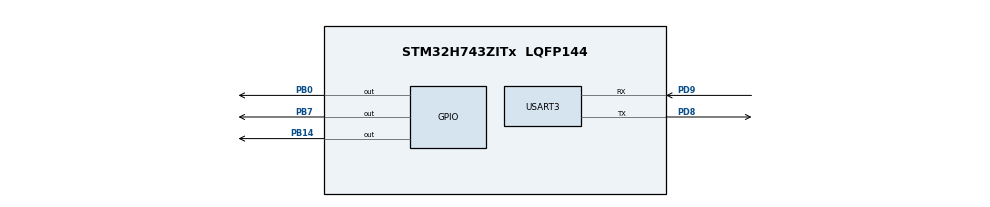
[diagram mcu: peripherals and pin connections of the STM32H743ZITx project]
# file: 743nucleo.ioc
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CORTEX_M7.AccessPermission-Cortex_Memory_Protection_Unit_Region0_Settings=MPU_REGION_PRIV_RO_URO
CORTEX_M7.AccessPermission-Cortex_Memory_Protection_Unit_Region1_Settings=MPU_REGION_FULL_ACCESS
CORTEX_M7.AccessPermission-Cortex_Memory_Protection_Unit_Region2_Settings=MPU_REGION_FULL_ACCESS
CORTEX_M7.AccessPermission-Cortex_Memory_Protection_Unit_Region3_Settings=MPU_REGION_FULL_ACCESS
CORTEX_M7.AccessPermission-Cortex_Memory_Protection_Unit_Region4_Settings=MPU_REGION_FULL_ACCESS
CORTEX_M7.AccessPermission-Cortex_Memory_Protection_Unit_Region5_Settings=MPU_REGION_FULL_ACCESS
CORTEX_M7.AccessPermission-Cortex_Memory_Protection_Unit_Region6_Settings=MPU_REGION_FULL_ACCESS
CORTEX_M7.BaseAddress-Cortex_Memory_Protection_Unit_Region0_Settings=0x08000000
CORTEX_M7.BaseAddress-Cortex_Memory_Protection_Unit_Region1_Settings=0x24000000
CORTEX_M7.BaseAddress-Cortex_Memory_Protection_Unit_Region2_Settings=0x30000000
CORTEX_M7.BaseAddress-Cortex_Memory_Protection_Unit_Region3_Settings=0x30020000
CORTEX_M7.BaseAddress-Cortex_Memory_Protection_Unit_Region4_Settings=0x30040000
CORTEX_M7.BaseAddress-Cortex_Memory_Protection_Unit_Region5_Settings=0x38000000
CORTEX_M7.BaseAddress-Cortex_Memory_Protection_Unit_Region6_Settings=0x38800000
CORTEX_M7.CPU_DCache=Enabled
CORTEX_M7.CPU_ICache=Enabled
CORTEX_M7.Enable-Cortex_Memory_Protection_Unit_Region0_Settings=MPU_REGION_ENABLE
CORTEX_M7.Enable-Cortex_Memory_Protection_Unit_Region1_Settings=MPU_REGION_ENABLE
CORTEX_M7.Enable-Cortex_Memory_Protection_Unit_Region2_Settings=MPU_REGION_ENABLE
CORTEX_M7.Enable-Cortex_Memory_Protection_Unit_Region3_Settings=MPU_REGION_ENABLE
CORTEX_M7.Enable-Cortex_Memory_Protection_Unit_Region4_Settings=MPU_REGION_ENABLE
CORTEX_M7.Enable-Cortex_Memory_Protection_Unit_Region5_Settings=MPU_REGION_ENABLE
CORTEX_M7.Enable-Cortex_Memory_Protection_Unit_Region6_Settings=MPU_REGION_ENABLE
CORTEX_M7.IsBufferable-Cortex_Memory_Protection_Unit_Region1_Settings=MPU_ACCESS_NOT_BUFFERABLE
CORTEX_M7.IsCacheable-Cortex_Memory_Protection_Unit_Region0_Settings=MPU_ACCESS_CACHEABLE
CORTEX_M7.IsCacheable-Cortex_Memory_Protection_Unit_Region1_Settings=MPU_ACCESS_CACHEABLE
CORTEX_M7.IsCacheable-Cortex_Memory_Protection_Unit_Region2_Settings=MPU_ACCESS_CACHEABLE
CORTEX_M7.IsCacheable-Cortex_Memory_Protection_Unit_Region3_Settings=MPU_ACCESS_CACHEABLE
CORTEX_M7.IsCacheable-Cortex_Memory_Protection_Unit_Region4_Settings=MPU_ACCESS_CACHEABLE
CORTEX_M7.IsCacheable-Cortex_Memory_Protection_Unit_Region5_Settings=MPU_ACCESS_CACHEABLE
CORTEX_M7.IsCacheable-Cortex_Memory_Protection_Unit_Region6_Settings=MPU_ACCESS_CACHEABLE
CORTEX_M7.IsShareable-Cortex_Memory_Protection_Unit_Region0_Settings=MPU_ACCESS_SHAREABLE
CORTEX_M7.IsShareable-Cortex_Memory_Protection_Unit_Region1_Settings=MPU_ACCESS_SHAREABLE
CORTEX_M7.IsShareable-Cortex_Memory_Protection_Unit_Region2_Settings=MPU_ACCESS_SHAREABLE
CORTEX_M7.IsShareable-Cortex_Memory_Protection_Unit_Region3_Settings=MPU_ACCESS_SHAREABLE
CORTEX_M7.IsShareable-Cortex_Memory_Protection_Unit_Region4_Settings=MPU_ACCESS_SHAREABLE
CORTEX_M7.IsShareable-Cortex_Memory_Protection_Unit_Region5_Settings=MPU_ACCESS_SHAREABLE
CORTEX_M7.IsShareable-Cortex_Memory_Protection_Unit_Region6_Settings=MPU_ACCESS_SHAREABLE
CORTEX_M7.MPU_Control=MPU_PRIVILEGED_DEFAULT
CORTEX_M7.Size-Cortex_Memory_Protection_Unit_Region0_Settings=MPU_REGION_SIZE_2MB
CORTEX_M7.Size-Cortex_Memory_Protection_Unit_Region1_Settings=MPU_REGION_SIZE_512KB
CORTEX_M7.Size-Cortex_Memory_Protection_Unit_Region2_Settings=MPU_REGION_SIZE_128KB
CORTEX_M7.Size-Cortex_Memory_Protection_Unit_Region3_Settings=MPU_REGION_SIZE_128KB
CORTEX_M7.Size-Cortex_Memory_Protection_Unit_Region4_Settings=MPU_REGION_SIZE_32KB
CORTEX_M7.Size-Cortex_Memory_Protection_Unit_Region5_Settings=MPU_REGION_SIZE_64KB
CORTEX_M7.Size-Cortex_Memory_Protection_Unit_Region6_Settings=MPU_REGION_SIZE_4KB
Dma.Request0=USART3_RX
Dma.Request1=USART3_TX
Dma.USART3_RX.0.Direction=DMA_PERIPH_TO_MEMORY
Dma.USART3_RX.0.EventEnable=DISABLE
Dma.USART3_RX.0.FIFOMode=DMA_FIFOMODE_DISABLE
Dma.USART3_RX.0.Instance=DMA1_Stream0
Dma.USART3_RX.0.MemDataAlignment=DMA_MDATAALIGN_BYTE
Dma.USART3_RX.0.MemInc=DMA_MINC_ENABLE
Dma.USART3_RX.0.Mode=DMA_NORMAL
Dma.USART3_RX.0.PeriphDataAlignment=DMA_PDATAALIGN_BYTE
Dma.USART3_RX.0.PeriphInc=DMA_PINC_DISABLE
Dma.USART3_RX.0.Polarity=HAL_DMAMUX_REQ_GEN_RISING
Dma.USART3_RX.0.Priority=DMA_PRIORITY_LOW
Dma.USART3_RX.0.RequestNumber=1
Dma.USART3_RX.0.SignalID=NONE
Dma.USART3_RX.0.SyncEnable=DISABLE
Dma.USART3_RX.0.SyncPolarity=HAL_DMAMUX_SYNC_NO_EVENT
Dma.USART3_RX.0.SyncRequestNumber=1
Dma.USART3_RX.0.SyncSignalID=NONE
Dma.USART3_TX.1.Direction=DMA_MEMORY_TO_PERIPH
Dma.USART3_TX.1.EventEnable=DISABLE
Dma.USART3_TX.1.FIFOMode=DMA_FIFOMODE_DISABLE
Dma.USART3_TX.1.Instance=DMA1_Stream1
Dma.USART3_TX.1.MemDataAlignment=DMA_MDATAALIGN_BYTE
Dma.USART3_TX.1.MemInc=DMA_MINC_ENABLE
Dma.USART3_TX.1.Mode=DMA_NORMAL
Dma.USART3_TX.1.PeriphDataAlignment=DMA_PDATAALIGN_BYTE
Dma.USART3_TX.1.PeriphInc=DMA_PINC_DISABLE
Dma.USART3_TX.1.Polarity=HAL_DMAMUX_REQ_GEN_RISING
Dma.USART3_TX.1.Priority=DMA_PRIORITY_LOW
Dma.USART3_TX.1.RequestNumber=1
Dma.USART3_TX.1.SignalID=NONE
Dma.USART3_TX.1.SyncEnable=DISABLE
Dma.USART3_TX.1.SyncPolarity=HAL_DMAMUX_SYNC_NO_EVENT
Dma.USART3_TX.1.SyncRequestNumber=1
Dma.USART3_TX.1.SyncSignalID=NONE
FREERTOS.BinarySemaphores01=myBinarySem01,Dynamic,NULL;myBinarySem02,Dynamic,NULL;myBinarySem03,Dynamic,NULL;myBinarySem04,Dynamic,NULL
FREERTOS.Mutexes01=myMutex01,Dynamic,NULL;myMutex02,Dynamic,NULL
FREERTOS.Queues01=myQueue01,16,uint16_t,0,Dynamic,NULL,NULL;myQueue02,16,uint16_t,0,Dynamic,NULL,NULL
FREERTOS.Tasks01=defaultTask,0,128,StartDefaultTask,Default,NULL,Dynamic,NULL,NULL;myTask02,-3,128,StartTask02,Default,NULL,Dynamic,NULL,NULL;myTask03,-3,128,StartTask03,Default,NULL,Dynamic,NULL,NULL;myTask04,-3,128,StartTask04,Default,NULL,Dynamic,NULL,NULL
FREERTOS.configGENERATE_RUN_TIME_STATS=1
FREERTOS.configUSE_STATS_FORMATTING_FUNCTIONS=1
FREERTOS.configUSE_TRACE_FACILITY=1
Mcu.Family=STM32H7
Mcu.Name=STM32H743ZITx
Mcu.Package=LQFP144
NVIC.DMA1_Stream0_IRQn=true\:5\:0\:false\:false\:true\:true\:false\:true
NVIC.DMA1_Stream1_IRQn=true\:5\:0\:false\:false\:true\:true\:false\:true
NVIC.PriorityGroup=NVIC_PRIORITYGROUP_4
NVIC.TIM7_IRQn=true\:0\:0\:false\:false\:true\:false\:false\:true
NVIC.TimeBase=TIM7_IRQn
NVIC.TimeBaseIP=TIM7
NVIC.USART3_IRQn=true\:5\:0\:false\:false\:true\:true\:true\:true
PA13\ (JTMS/SWDIO).Mode=Serial_Wire
PA13\ (JTMS/SWDIO).Signal=SYS_JTMS-SWDIO
PA14\ (JTCK/SWCLK).Mode=Serial_Wire
PA14\ (JTCK/SWCLK).Signal=SYS_JTCK-SWCLK
PB0.Signal=GPIO_Output
PB14.Signal=GPIO_Output
PB7.Signal=GPIO_Output
PC14-OSC32_IN\ (OSC32_IN).Mode=LSE-External-Oscillator
PC14-OSC32_IN\ (OSC32_IN).Signal=RCC_OSC32_IN
PC15-OSC32_OUT\ (OSC32_OUT).Mode=LSE-External-Oscillator
PC15-OSC32_OUT\ (OSC32_OUT).Signal=RCC_OSC32_OUT
PD8.GPIO_Speed=GPIO_SPEED_FREQ_VERY_HIGH
PD8.Mode=Asynchronous
PD8.Signal=USART3_TX
PD9.GPIO_Speed=GPIO_SPEED_FREQ_VERY_HIGH
PD9.Mode=Asynchronous
PD9.Signal=USART3_RX
PG11.GPIO_Speed=GPIO_SPEED_FREQ_VERY_HIGH
PG11.Signal=ETH_TX_EN
PG13.GPIO_Speed=GPIO_SPEED_FREQ_VERY_HIGH
PG13.Signal=ETH_TXD0
PH0-OSC_IN\ (PH0).Mode=HSE-External-Clock-Source
PH0-OSC_IN\ (PH0).Signal=RCC_OSC_IN
PH1-OSC_OUT\ (PH1).Mode=HSE-External-Clock-Source
PH1-OSC_OUT\ (PH1).Signal=RCC_OSC_OUT
ProjectManager.HeapSize=0x8000
ProjectManager.StackSize=0x8000
ProjectManager.TargetToolchain=MDK-ARM V5
RCC.ADCFreq_Value=16125000
RCC.APB1Freq_Value=100000000
RCC.APB2Freq_Value=100000000
RCC.APB3Freq_Value=100000000
RCC.APB4Freq_Value=100000000
RCC.CortexFreq_Value=400000000
RCC.D1PPRE=RCC_APB3_DIV2
RCC.D2PPRE1=RCC_APB1_DIV2
RCC.D2PPRE2=RCC_APB2_DIV2
RCC.D3PPRE=RCC_APB4_DIV2
RCC.DIVM1=1
RCC.DIVN1=100
RCC.FLatency=FLASH_LATENCY_7
RCC.HCLKFreq_Value=200000000
RCC.HPRE=RCC_HCLK_DIV2
RCC.HSE_VALUE=8000000
RCC.PLLSourceVirtual=RCC_PLLSOURCE_HSE
RCC.PWR_Regulator_Voltage_Scale=PWR_REGULATOR_VOLTAGE_SCALE1
RCC.RCC_MCO1Source=RCC_MCO1SOURCE_PLL1QCLK
RCC.RCC_MCODiv1=RCC_MCODIV_8
RCC.SYSCLKFreq_VALUE=400000000
RCC.SYSCLKSource=RCC_SYSCLKSOURCE_PLLCLK
RCC.USBFreq_Value=400000000
USART3.VirtualMode-Asynchronous=VM_ASYNC
VP_FREERTOS_VS_CMSIS_V1.Mode=CMSIS_V1
VP_SYS_VS_tim7.Mode=TIM7
VP_TIM2_VS_ClockSourceINT.Mode=Internal
board=custom

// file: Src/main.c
/* USER CODE BEGIN Header */
/**
  ******************************************************************************
  * @file           : main.c
  * @brief          : Main program body
  ******************************************************************************
  * @attention
  *
  * <h2><center>&copy; Copyright (c) 2019 STMicroelectronics.
  * All rights reserved.</center></h2>
  *
  * This software component is licensed by ST under BSD 3-Clause license,
  * the "License"; You may not use this file except in compliance with the
  * License. You may obtain a copy of the License at:
  *                        opensource.org/licenses/BSD-3-Clause
  *
  ******************************************************************************
  */
/* USER CODE END Header */

#include "main.h"
#include "cmsis_os.h"
#include "dma.h"
#include "tim.h"
#include "usart.h"
#include "gpio.h"

/* USER CODE BEGIN Includes */
#include "stdio.h"

/* USER CODE END Includes */

void SystemClock_Config(void);
static void MPU_Config(void);
void MX_FREERTOS_Init(void);

int main(void)
{

  /* MPU Configuration--------------------------------------------------------*/
  MPU_Config();

  /* Enable I-Cache---------------------------------------------------------*/
  SCB_EnableICache();

  /* Enable D-Cache---------------------------------------------------------*/
  SCB_EnableDCache();

  /* MCU Configuration--------------------------------------------------------*/

  /* Reset of all peripherals, Initializes the Flash interface and the Systick. */
  HAL_Init();

  /* Configure the system clock */
  SystemClock_Config();

  /* Initialize all configured peripherals */
  MX_GPIO_Init();
  MX_DMA_Init();
  MX_USART3_UART_Init();
  MX_TIM2_Init();
  /* USER CODE BEGIN 2 */
//HAL_UART_Transmit(&huart3,"1212121212122121",15,1000);
printf("os start 1212122112121221212");

  /* USER CODE END 2 */

  /* Call init function for freertos objects (in freertos.c) */
  MX_FREERTOS_Init();

  /* Start scheduler */
  osKernelStart();

  /* We should never get here as control is now taken by the scheduler */

  /* Infinite loop */
  while (1)
  {

  }
}

void SystemClock_Config(void)
{
  RCC_OscInitTypeDef RCC_OscInitStruct = {0};
  RCC_ClkInitTypeDef RCC_ClkInitStruct = {0};
  RCC_PeriphCLKInitTypeDef PeriphClkInitStruct = {0};

  /** Supply configuration update enable
  */
  MODIFY_REG(PWR->CR3, PWR_CR3_SCUEN, 0);
  /** Configure the main internal regulator output voltage
  */
  __HAL_PWR_VOLTAGESCALING_CONFIG(PWR_REGULATOR_VOLTAGE_SCALE1);

  while ((PWR->D3CR & (PWR_D3CR_VOSRDY)) != PWR_D3CR_VOSRDY)
  {

  }
  /** Initializes the CPU, AHB and APB busses clocks
  */
  RCC_OscInitStruct.OscillatorType = RCC_OSCILLATORTYPE_HSE;
  RCC_OscInitStruct.HSEState = RCC_HSE_BYPASS;
  RCC_OscInitStruct.PLL.PLLState = RCC_PLL_ON;
  RCC_OscInitStruct.PLL.PLLSource = RCC_PLLSOURCE_HSE;
  RCC_OscInitStruct.PLL.PLLM = 1;
  RCC_OscInitStruct.PLL.PLLN = 100;
  RCC_OscInitStruct.PLL.PLLP = 2;
  RCC_OscInitStruct.PLL.PLLQ = 2;
  RCC_OscInitStruct.PLL.PLLR = 2;
  RCC_OscInitStruct.PLL.PLLRGE = RCC_PLL1VCIRANGE_3;
  RCC_OscInitStruct.PLL.PLLVCOSEL = RCC_PLL1VCOWIDE;
  RCC_OscInitStruct.PLL.PLLFRACN = 0;
  if (HAL_RCC_OscConfig(&RCC_OscInitStruct) != HAL_OK)
  {
    Error_Handler();
  }
  /** Initializes the CPU, AHB and APB busses clocks
  */
  RCC_ClkInitStruct.ClockType = RCC_CLOCKTYPE_HCLK|RCC_CLOCKTYPE_SYSCLK
                              |RCC_CLOCKTYPE_PCLK1|RCC_CLOCKTYPE_PCLK2
                              |RCC_CLOCKTYPE_D3PCLK1|RCC_CLOCKTYPE_D1PCLK1;
  RCC_ClkInitStruct.SYSCLKSource = RCC_SYSCLKSOURCE_PLLCLK;
  RCC_ClkInitStruct.SYSCLKDivider = RCC_SYSCLK_DIV1;
  RCC_ClkInitStruct.AHBCLKDivider = RCC_HCLK_DIV2;
  RCC_ClkInitStruct.APB3CLKDivider = RCC_APB3_DIV2;
  RCC_ClkInitStruct.APB1CLKDivider = RCC_APB1_DIV2;
  RCC_ClkInitStruct.APB2CLKDivider = RCC_APB2_DIV2;
  RCC_ClkInitStruct.APB4CLKDivider = RCC_APB4_DIV2;

  if (HAL_RCC_ClockConfig(&RCC_ClkInitStruct, FLASH_LATENCY_7) != HAL_OK)
  {
    Error_Handler();
  }
  PeriphClkInitStruct.PeriphClockSelection = RCC_PERIPHCLK_USART3;
  PeriphClkInitStruct.Usart234578ClockSelection = RCC_USART234578CLKSOURCE_D2PCLK1;
  if (HAL_RCCEx_PeriphCLKConfig(&PeriphClkInitStruct) != HAL_OK)
  {
    Error_Handler();
  }
}

/* MPU Configuration */

void MPU_Config(void)
{
  MPU_Region_InitTypeDef MPU_InitStruct = {0};

  /* Disables the MPU */
  HAL_MPU_Disable();
  /** Initializes and configures the Region and the memory to be protected
  */
  MPU_InitStruct.Enable = MPU_REGION_ENABLE;
  MPU_InitStruct.Number = MPU_REGION_NUMBER0;
  MPU_InitStruct.BaseAddress = 0x08000000;
  MPU_InitStruct.Size = MPU_REGION_SIZE_2MB;
  MPU_InitStruct.SubRegionDisable = 0x0;
  MPU_InitStruct.TypeExtField = MPU_TEX_LEVEL0;
  MPU_InitStruct.AccessPermission = MPU_REGION_PRIV_RO_URO;
  MPU_InitStruct.DisableExec = MPU_INSTRUCTION_ACCESS_ENABLE;
  MPU_InitStruct.IsShareable = MPU_ACCESS_SHAREABLE;
  MPU_InitStruct.IsCacheable = MPU_ACCESS_CACHEABLE;
  MPU_InitStruct.IsBufferable = MPU_ACCESS_NOT_BUFFERABLE;

  HAL_MPU_ConfigRegion(&MPU_InitStruct);
  /** Initializes and configures the Region and the memory to be protected
  */
  MPU_InitStruct.Enable = MPU_REGION_ENABLE;
  MPU_InitStruct.Number = MPU_REGION_NUMBER1;
  MPU_InitStruct.BaseAddress = 0x24000000;
  MPU_InitStruct.Size = MPU_REGION_SIZE_512KB;
  MPU_InitStruct.SubRegionDisable = 0x0;
  MPU_InitStruct.TypeExtField = MPU_TEX_LEVEL0;
  MPU_InitStruct.AccessPermission = MPU_REGION_FULL_ACCESS;
  MPU_InitStruct.DisableExec = MPU_INSTRUCTION_ACCESS_ENABLE;
  MPU_InitStruct.IsShareable = MPU_ACCESS_SHAREABLE;
  MPU_InitStruct.IsCacheable = MPU_ACCESS_CACHEABLE;
  MPU_InitStruct.IsBufferable = MPU_ACCESS_NOT_BUFFERABLE;

  HAL_MPU_ConfigRegion(&MPU_InitStruct);
  /** Initializes and configures the Region and the memory to be protected
  */
  MPU_InitStruct.Enable = MPU_REGION_ENABLE;
  MPU_InitStruct.Number = MPU_REGION_NUMBER2;
  MPU_InitStruct.BaseAddress = 0x30000000;
  MPU_InitStruct.Size = MPU_REGION_SIZE_128KB;
  MPU_InitStruct.SubRegionDisable = 0x0;
  MPU_InitStruct.TypeExtField = MPU_TEX_LEVEL0;
  MPU_InitStruct.AccessPermission = MPU_REGION_FULL_ACCESS;
  MPU_InitStruct.DisableExec = MPU_INSTRUCTION_ACCESS_ENABLE;
  MPU_InitStruct.IsShareable = MPU_ACCESS_SHAREABLE;
  MPU_InitStruct.IsCacheable = MPU_ACCESS_CACHEABLE;
  MPU_InitStruct.IsBufferable = MPU_ACCESS_NOT_BUFFERABLE;

  HAL_MPU_ConfigRegion(&MPU_InitStruct);
  /** Initializes and configures the Region and the memory to be protected
  */
  MPU_InitStruct.Enable = MPU_REGION_ENABLE;
  MPU_InitStruct.Number = MPU_REGION_NUMBER3;
  MPU_InitStruct.BaseAddress = 0x30020000;
  MPU_InitStruct.Size = MPU_REGION_SIZE_128KB;
  MPU_InitStruct.SubRegionDisable = 0x0;
  MPU_InitStruct.TypeExtField = MPU_TEX_LEVEL0;
  MPU_InitStruct.AccessPermission = MPU_REGION_FULL_ACCESS;
  MPU_InitStruct.DisableExec = MPU_INSTRUCTION_ACCESS_ENABLE;
  MPU_InitStruct.IsShareable = MPU_ACCESS_SHAREABLE;
  MPU_InitStruct.IsCacheable = MPU_ACCESS_CACHEABLE;
  MPU_InitStruct.IsBufferable = MPU_ACCESS_NOT_BUFFERABLE;

  HAL_MPU_ConfigRegion(&MPU_InitStruct);
  /** Initializes and configures the Region and the memory to be protected
  */
  MPU_InitStruct.Enable = MPU_REGION_ENABLE;
  MPU_InitStruct.Number = MPU_REGION_NUMBER4;
  MPU_InitStruct.BaseAddress = 0x30040000;
  MPU_InitStruct.Size = MPU_REGION_SIZE_32KB;
  MPU_InitStruct.SubRegionDisable = 0x0;
  MPU_InitStruct.TypeExtField = MPU_TEX_LEVEL0;
  MPU_InitStruct.AccessPermission = MPU_REGION_FULL_ACCESS;
  MPU_InitStruct.DisableExec = MPU_INSTRUCTION_ACCESS_ENABLE;
  MPU_InitStruct.IsShareable = MPU_ACCESS_SHAREABLE;
  MPU_InitStruct.IsCacheable = MPU_ACCESS_CACHEABLE;
  MPU_InitStruct.IsBufferable = MPU_ACCESS_NOT_BUFFERABLE;

  HAL_MPU_ConfigRegion(&MPU_InitStruct);
  /** Initializes and configures the Region and the memory to be protected
  */
  MPU_InitStruct.Enable = MPU_REGION_ENABLE;
  MPU_InitStruct.Number = MPU_REGION_NUMBER5;
  MPU_InitStruct.BaseAddress = 0x38000000;
  MPU_InitStruct.Size = MPU_REGION_SIZE_64KB;
  MPU_InitStruct.SubRegionDisable = 0x0;
  MPU_InitStruct.TypeExtField = MPU_TEX_LEVEL0;
  MPU_InitStruct.AccessPermission = MPU_REGION_FULL_ACCESS;
  MPU_InitStruct.DisableExec = MPU_INSTRUCTION_ACCESS_ENABLE;
  MPU_InitStruct.IsShareable = MPU_ACCESS_SHAREABLE;
  MPU_InitStruct.IsCacheable = MPU_ACCESS_CACHEABLE;
  MPU_InitStruct.IsBufferable = MPU_ACCESS_NOT_BUFFERABLE;

  HAL_MPU_ConfigRegion(&MPU_InitStruct);
  /** Initializes and configures the Region and the memory to be protected
  */
  MPU_InitStruct.Enable = MPU_REGION_ENABLE;
  MPU_InitStruct.Number = MPU_REGION_NUMBER6;
  MPU_InitStruct.BaseAddress = 0x38800000;
  MPU_InitStruct.Size = MPU_REGION_SIZE_4KB;
  MPU_InitStruct.SubRegionDisable = 0x0;
  MPU_InitStruct.TypeExtField = MPU_TEX_LEVEL0;
  MPU_InitStruct.AccessPermission = MPU_REGION_FULL_ACCESS;
  MPU_InitStruct.DisableExec = MPU_INSTRUCTION_ACCESS_ENABLE;
  MPU_InitStruct.IsShareable = MPU_ACCESS_SHAREABLE;
  MPU_InitStruct.IsCacheable = MPU_ACCESS_CACHEABLE;
  MPU_InitStruct.IsBufferable = MPU_ACCESS_NOT_BUFFERABLE;

  HAL_MPU_ConfigRegion(&MPU_InitStruct);
  /* Enables the MPU */
  HAL_MPU_Enable(MPU_PRIVILEGED_DEFAULT);

}
void HAL_TIM_PeriodElapsedCallback(TIM_HandleTypeDef *htim)
{
  if (htim->Instance == TIM7) {
    HAL_IncTick();
  }
}

void Error_Handler(void)
{
}

/************************ (C) COPYRIGHT STMicroelectronics *****END OF FILE****/

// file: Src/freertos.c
/* USER CODE BEGIN Header */
/**
  ******************************************************************************
  * File Name          : freertos.c
  * Description        : Code for freertos applications
  ******************************************************************************
  * @attention
  *
  * <h2><center>&copy; Copyright (c) 2019 STMicroelectronics.
  * All rights reserved.</center></h2>
  *
  * This software component is licensed by ST under Ultimate Liberty license
  * SLA0044, the "License"; You may not use this file except in compliance with
  * the License. You may obtain a copy of the License at:
  *                             www.st.com/SLA0044
  *
  ******************************************************************************
  */
/* USER CODE END Header */

#include "FreeRTOS.h"
#include "task.h"
#include "main.h"
#include "cmsis_os.h"

osThreadId defaultTaskHandle;
osThreadId myTask02Handle;
osThreadId myTask03Handle;
osThreadId myTask04Handle;
osMessageQId myQueue01Handle;
osMessageQId myQueue02Handle;
osMutexId myMutex01Handle;
osMutexId myMutex02Handle;
osSemaphoreId myBinarySem01Handle;
osSemaphoreId myBinarySem02Handle;
osSemaphoreId myBinarySem03Handle;
osSemaphoreId myBinarySem04Handle;

void StartDefaultTask(void const * argument);
void StartTask02(void const * argument);
void StartTask03(void const * argument);
void StartTask04(void const * argument);

void MX_FREERTOS_Init(void); /* (MISRA C 2004 rule 8.1) */

/* Hook prototypes */
void configureTimerForRunTimeStats(void);
unsigned long getRunTimeCounterValue(void);

/* USER CODE BEGIN 1 */
/* Functions needed when configGENERATE_RUN_TIME_STATS is on */
__weak void configureTimerForRunTimeStats(void)
{

}

__weak unsigned long getRunTimeCounterValue(void)
{
return 0;
}
/* USER CODE END 1 */

void MX_FREERTOS_Init(void) {

  /* Create the mutex(es) */
  /* definition and creation of myMutex01 */
  osMutexDef(myMutex01);
  myMutex01Handle = osMutexCreate(osMutex(myMutex01));

  /* definition and creation of myMutex02 */
  osMutexDef(myMutex02);
  myMutex02Handle = osMutexCreate(osMutex(myMutex02));

  /* Create the semaphores(s) */
  /* definition and creation of myBinarySem01 */
  osSemaphoreDef(myBinarySem01);
  myBinarySem01Handle = osSemaphoreCreate(osSemaphore(myBinarySem01), 1);

  /* definition and creation of myBinarySem02 */
  osSemaphoreDef(myBinarySem02);
  myBinarySem02Handle = osSemaphoreCreate(osSemaphore(myBinarySem02), 1);

  /* definition and creation of myBinarySem03 */
  osSemaphoreDef(myBinarySem03);
  myBinarySem03Handle = osSemaphoreCreate(osSemaphore(myBinarySem03), 1);

  /* definition and creation of myBinarySem04 */
  osSemaphoreDef(myBinarySem04);
  myBinarySem04Handle = osSemaphoreCreate(osSemaphore(myBinarySem04), 1);

  /* Create the queue(s) */
  /* definition and creation of myQueue01 */
  osMessageQDef(myQueue01, 16, uint16_t);
  myQueue01Handle = osMessageCreate(osMessageQ(myQueue01), NULL);

  /* definition and creation of myQueue02 */
  osMessageQDef(myQueue02, 16, uint16_t);
  myQueue02Handle = osMessageCreate(osMessageQ(myQueue02), NULL);

  /* Create the thread(s) */
  /* definition and creation of defaultTask */
  osThreadDef(defaultTask, StartDefaultTask, osPriorityNormal, 0, 128);
  defaultTaskHandle = osThreadCreate(osThread(defaultTask), NULL);

  /* definition and creation of myTask02 */
  osThreadDef(myTask02, StartTask02, osPriorityIdle, 0, 128);
  myTask02Handle = osThreadCreate(osThread(myTask02), NULL);

  /* definition and creation of myTask03 */
  osThreadDef(myTask03, StartTask03, osPriorityIdle, 0, 128);
  myTask03Handle = osThreadCreate(osThread(myTask03), NULL);

  /* definition and creation of myTask04 */
  osThreadDef(myTask04, StartTask04, osPriorityIdle, 0, 128);
  myTask04Handle = osThreadCreate(osThread(myTask04), NULL);

}

void StartDefaultTask(void const * argument)
{

  for(;;)
  {
    osDelay(1);
  }
}

void StartTask02(void const * argument)
{
  for(;;)
  {
    osDelay(1);
  }
}

void StartTask03(void const * argument)
{
  for(;;)
  {
    osDelay(1);
  }
}

void StartTask04(void const * argument)
{
  for(;;)
  {
    osDelay(1);
  }
}

/************************ (C) COPYRIGHT STMicroelectronics *****END OF FILE****/
